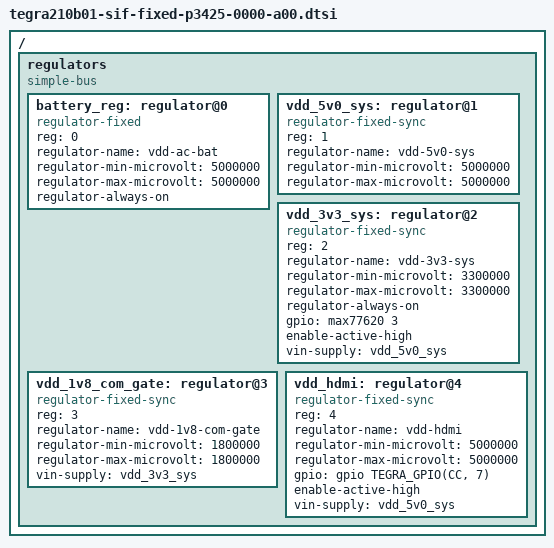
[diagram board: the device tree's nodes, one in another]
/*
 * Copyright (c) 2018, NVIDIA CORPORATION.  All rights reserved.
 *
 * This program is free software; you can redistribute it and/or modify
 * it under the terms of the GNU General Public License as published by
 * the Free Software Foundation; either version 2 of the License, or
 * (at your option) any later version.
 *
 * This program is distributed in the hope that it will be useful, but WITHOUT
 * ANY WARRANTY; without even the implied warranty of MERCHANTABILITY or
 * FITNESS FOR A PARTICULAR PURPOSE.  See the GNU General Public License for
 * more details.
 *
 * You should have received a copy of the GNU General Public License along
 * with this program; if not, write to the Free Software Foundation, Inc.,
 * 51 Franklin Street, Fifth Floor, Boston, MA  02110-1301, USA.
 */

#include <dt-bindings/gpio/tegra-gpio.h>

/ {
	regulators {
		compatible = "simple-bus";
		device_type = "fixed-regulators";
		#address-cells = <1>;
		#size-cells = <0>;

		battery_reg: regulator@0 {
			compatible = "regulator-fixed";
			reg = <0>;
			regulator-name = "vdd-ac-bat";
			regulator-min-microvolt = <5000000>;
			regulator-max-microvolt = <5000000>;
			regulator-always-on;
		};

		vdd_5v0_sys: regulator@1 { /* DC 5V INPUT */
			compatible = "regulator-fixed-sync";
			reg = <1>;
			regulator-name = "vdd-5v0-sys";
			regulator-min-microvolt = <5000000>;
			regulator-max-microvolt = <5000000>;
		};

		vdd_3v3_sys: regulator@2 {
			compatible = "regulator-fixed-sync";
			reg = <2>;
			regulator-name = "vdd-3v3-sys";
			regulator-min-microvolt = <3300000>;
			regulator-max-microvolt = <3300000>;
			regulator-always-on;
			gpio = <&max77620 3 0>;
			enable-active-high;
			vin-supply = <&vdd_5v0_sys>;
		};

		vdd_1v8_com_gate: regulator@3 {
			compatible = "regulator-fixed-sync";
			reg = <3>;
			regulator-name = "vdd-1v8-com-gate";
			regulator-min-microvolt = <1800000>;
			regulator-max-microvolt = <1800000>;
			vin-supply = <&vdd_3v3_sys>;
		};

		vdd_hdmi: regulator@4 {
			compatible = "regulator-fixed-sync";
			reg = <4>;
			regulator-name = "vdd-hdmi";
			regulator-min-microvolt = <5000000>;
			regulator-max-microvolt = <5000000>;
			gpio = <&gpio TEGRA_GPIO(CC, 7) 0>;
			enable-active-high;
			vin-supply = <&vdd_5v0_sys>;
		};
	};
};
